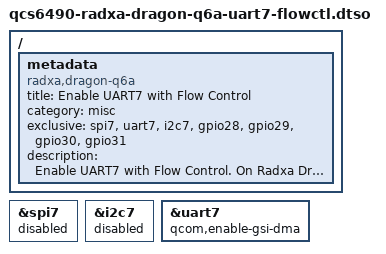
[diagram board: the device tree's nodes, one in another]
// SPDX-License-Identifier: BSD-3-Clause
/*
 * Copyright (c) 2026 Radxa Computer (Shenzhen) Co., Ltd.
 */

/dts-v1/;
/plugin/;

/ {
	metadata {
		title = "Enable UART7 with Flow Control";
		compatible = "radxa,dragon-q6a";
		category = "misc";
		exclusive = "spi7", "uart7", "i2c7", "gpio28", "gpio29", "gpio30", "gpio31";
		description = "Enable UART7 with Flow Control.
On Radxa Dragon Q6A, this is pin 11(rts), 31(cts), 32(tx), 29(rx).";
	};
};

&spi7 {
	status = "disabled";
};

&i2c7 {
	status = "disabled";
};

&uart7 {
	qcom,enable-gsi-dma;
	status = "okay";
};
